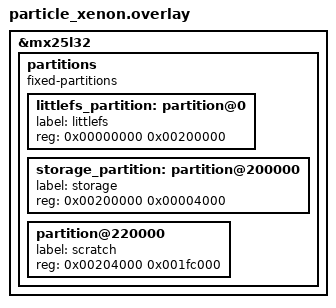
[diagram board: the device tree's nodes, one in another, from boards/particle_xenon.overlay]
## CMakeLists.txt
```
# SPDX-License-Identifier: Apache-2.0

cmake_minimum_required(VERSION 3.28.0)

find_package(Zephyr REQUIRED HINTS $ENV{ZEPHYR_BASE})
project(fs_shell)

FILE(GLOB app_sources src/*.c)
target_sources(app PRIVATE ${app_sources})
```

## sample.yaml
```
sample:
  description: FS shell sample
  name: FS shell
common:
  tags:
    - shell
    - filesystem
  harness: keyboard
tests:
  sample.shell.filesystem:
    platform_allow:
      - reel_board
      - mimxrt1060_evk/mimxrt1062/qspi
      - mr_canhubk3
      - native_sim
      - s32z2xxdc2/s32z270/rtu0
      - s32z2xxdc2/s32z270/rtu1
      - s32z2xxdc2@D/s32z270/rtu0
      - s32z2xxdc2@D/s32z270/rtu1
      - s32k5xxcvb/s32k566/m7
      - s32k5xxcvb/s32k566/r52
    integration_platforms:
      - native_sim
  sample.shell.filesystem.fuse:
    platform_allow:
      - native_sim
    extra_configs:
      - CONFIG_FUSE_FS_ACCESS=y
    # This test cannot be run in CI as we lack the fuse library
    skip: true
  sample.shell.filesystem.flash_load:
    tags:
      - flash_load
    platform_allow: nrf52dk/nrf52832
    extra_args: CONF_FILE=prj_flash_load.conf
    integration_platforms:
      - nrf52dk/nrf52832
```

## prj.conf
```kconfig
CONFIG_FLASH=y

CONFIG_LOG=y
#CONFIG_FS_LOG_LEVEL_DBG=y

CONFIG_HEAP_MEM_POOL_SIZE=16384

CONFIG_SHELL=y
CONFIG_SHELL_LOG_LEVEL_INF=y

CONFIG_FILE_SYSTEM=y
CONFIG_FILE_SYSTEM_SHELL=y


CONFIG_FILE_SYSTEM_LITTLEFS=y
CONFIG_FLASH_MAP=y
```

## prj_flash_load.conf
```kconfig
CONFIG_FLASH=y

CONFIG_LOG=y

CONFIG_HEAP_MEM_POOL_SIZE=16384

CONFIG_SHELL=y
CONFIG_SHELL_LOG_LEVEL_INF=y

CONFIG_FILE_SYSTEM=y
CONFIG_FILE_SYSTEM_SHELL=y

CONFIG_SHELL_BACKEND_SERIAL_RX_RING_BUFFER_SIZE=128

CONFIG_FILE_SYSTEM_LITTLEFS=y
CONFIG_FLASH_MAP=y
```

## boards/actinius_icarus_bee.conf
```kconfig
#
# Copyright (c) 2021 Actinius
#
# SPDX-License-Identifier: Apache-2.0
#
CONFIG_SPI=y
CONFIG_SPI_NOR_FLASH_LAYOUT_PAGE_SIZE=4096

CONFIG_MPU_ALLOW_FLASH_WRITE=y
```

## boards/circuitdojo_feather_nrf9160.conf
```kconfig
#
# Copyright (c) 2020 Circuit Dojo LLC
#
# SPDX-License-Identifier: Apache-2.0
#
CONFIG_SPI=y
CONFIG_SPI_NOR_FLASH_LAYOUT_PAGE_SIZE=4096
```

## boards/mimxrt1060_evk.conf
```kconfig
#
# Copyright (c) 2021 NXP.
# SPDX-License-Identifier: Apache-2.0
#

CONFIG_MPU_ALLOW_FLASH_WRITE=y
```

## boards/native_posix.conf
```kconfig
CONFIG_FUSE_FS_ACCESS=y
```

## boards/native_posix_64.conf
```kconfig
CONFIG_FUSE_FS_ACCESS=y
```

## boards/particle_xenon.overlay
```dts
/*
 * Copyright (c) 2019 Peter Bigot Consulting, LLC
 *
 * SPDX-License-Identifier: Apache-2.0
 */

/delete-node/ &storage_partition;

&mx25l32 {
	partitions {
		compatible = "fixed-partitions";
		#address-cells = <1>;
		#size-cells = <1>;

		/* This is the littlefs v1 file system pre-installed
		 * by Particle.
		 */
		littlefs_partition: partition@0 {
			label = "littlefs";
			reg = <0x00000000 0x00200000>;
		};
		/* A 16 KiBy partition to use for the test. */
		storage_partition: partition@200000 {
			label = "storage";
			reg = <0x00200000 0x00004000>;
		};
		/* A bigger partition for something else. */
		partition@220000 {
			label = "scratch";
			reg = <0x00204000 0x001fc000>;
		};
	};
};
```

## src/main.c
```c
/*
 * Copyright (c) 2019 Jan Van Winkel <jan.van_winkel@dxplore.eu>
 *
 * SPDX-License-Identifier: Apache-2.0
 */


#define LOG_LEVEL CONFIG_LOG_DEFAULT_LEVEL
#include <zephyr/logging/log.h>
LOG_MODULE_REGISTER(app);

int main(void)
{
	return 0;
}
```
